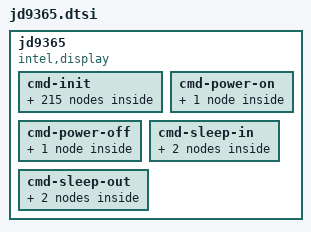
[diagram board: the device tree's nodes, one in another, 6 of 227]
	jd9365 {
		compatible = "intel,display";
		intel,display-resolution= <720 1280>;
		intel,display-dpi= <210 210>;

		/* MIPI-DSI video mode settings */
		intel,display-vid-hfp-hs-bytes = <60>;
		intel,display-vid-hbp-hs-bytes = <40>;
		intel,display-vid-hsa-hs-bytes = <30>;
		intel,display-vid-vfp-lines = <18>;
		intel,display-vid-vbp-lines = <12>;
		intel,display-vid-vsa-lines = <4>;

		intel,display-vid-mode = "pulses";
		intel,display-vid-id = <0>;
		intel,display-vid-pixel = "24packed";

		intel,display-reset = <1 1 0 5 1 50>;

		cmd-init {
			page0 {
				intel,cmd-type = <0x15>;
				intel,cmd-data = <0xE0 0x00>;
				intel,cmd-lp = <1>;
			};
			password-1 {
				intel,cmd-type = <0x15>;
				intel,cmd-data = <0xE1 0x93>;
				intel,cmd-lp = <1>;
			};
			password-2 {
				intel,cmd-type = <0x15>;
				intel,cmd-data = <0xE2 0x65>;
				intel,cmd-lp = <1>;
			};
			password-3 {
				intel,cmd-type = <0x15>;
				intel,cmd-data = <0xE3 0xF8>;
				intel,cmd-lp = <1>;
			};
			sequence_ctrl_1 {
				intel,cmd-type = <0x15>;
				intel,cmd-data = <0x70 0x10>;
				intel,cmd-lp = <1>;
			};
			sequence_ctrl_2 {
				intel,cmd-type = <0x15>;
				intel,cmd-data = <0x71 0x13>;
				intel,cmd-lp = <1>;
			};
			sequence_ctrl_3 {
				intel,cmd-type = <0x15>;
				intel,cmd-data = <0x72 0x06>;
				intel,cmd-lp = <1>;
			};
			sequence_ctrl_4 {
				intel,cmd-type = <0x15>;
				intel,cmd-data = <0x80 0x03>;
				intel,cmd-lp = <1>;
			};
			page1 {
				intel,cmd-type = <0x15>;
				intel,cmd-data = <0xE0 0x01>;
				intel,cmd-lp = <1>;
			};
			vcom_1 {
				intel,cmd-type = <0x15>;
				intel,cmd-data = <0x00 0x00>;
				intel,cmd-lp = <1>;
			};
			vcom_2 {
				intel,cmd-type = <0x15>;
				intel,cmd-data = <0x01 0xF4>;
				intel,cmd-lp = <1>;
			};
			vcom_3 {
				intel,cmd-type = <0x15>;
				intel,cmd-data = <0x03 0x00>;
				intel,cmd-lp = <1>;
			};
			vcom_4 {
				intel,cmd-type = <0x15>;
				intel,cmd-data = <0x04 0xFF>;
				intel,cmd-lp = <1>;
			};
			gamma_power_1 {
				intel,cmd-type = <0x15>;
				intel,cmd-data = <0x17 0x10>;
				intel,cmd-lp = <1>;
			};
			gamma_power_2 {
				intel,cmd-type = <0x15>;
				intel,cmd-data = <0x18 0x01>;
				intel,cmd-lp = <1>;
			};
			gamma_power_3 {
				intel,cmd-type = <0x15>;
				intel,cmd-data = <0x19 0x0E>;
				intel,cmd-lp = <1>;
			};
			gamma_power_4 {
				intel,cmd-type = <0x15>;
				intel,cmd-data = <0x1A 0x10>;
				intel,cmd-lp = <1>;
			};
			gamma_power_5 {
				intel,cmd-type = <0x15>;
				intel,cmd-data = <0x1B 0x01>;
				intel,cmd-lp = <1>;
			};
			gamma_power_6 {
				intel,cmd-type = <0x15>;
				intel,cmd-data = <0x1C 0x0E>;
				intel,cmd-lp = <1>;
			};
			gamma_power_7 {
				intel,cmd-type = <0x15>;
				intel,cmd-data = <0x1F 0x7E>;
				intel,cmd-lp = <1>;
			};
			gamma_power_8 {
				intel,cmd-type = <0x15>;
				intel,cmd-data = <0x20 0x24>;
				intel,cmd-lp = <1>;
			};
			gamma_power_9 {
				intel,cmd-type = <0x15>;
				intel,cmd-data = <0x21 0x24>;
				intel,cmd-lp = <1>;
			};
			gamma_power_10 {
				intel,cmd-type = <0x15>;
				intel,cmd-data = <0x12 0x4E>;
				intel,cmd-lp = <1>;
			};
			rgb_cyc_1 {
				intel,cmd-type = <0x15>;
				intel,cmd-data = <0x37 0x09>;
				intel,cmd-lp = <1>;
			};
			rgb_cyc_2 {
				intel,cmd-type = <0x15>;
				intel,cmd-data = <0x38 0x04>;
				intel,cmd-lp = <1>;
			};
			rgb_cyc_3 {
				intel,cmd-type = <0x15>;
				intel,cmd-data = <0x39 0x08>;
				intel,cmd-lp = <1>;
			};
			rgb_cyc_4 {
				intel,cmd-type = <0x15>;
				intel,cmd-data = <0x3A 0x12>;
				intel,cmd-lp = <1>;
			};
			rgb_cyc_5 {
				intel,cmd-type = <0x15>;
				intel,cmd-data = <0x3C 0x78>;
				intel,cmd-lp = <1>;
			};
			rgb_cyc_6 {
				intel,cmd-type = <0x15>;
				intel,cmd-data = <0x3D 0xFF>;
				intel,cmd-lp = <1>;
			};
			rgb_cyc_7 {
				intel,cmd-type = <0x15>;
				intel,cmd-data = <0x3E 0xFF>;
				intel,cmd-lp = <1>;
			};
			rgb_cyc_8 {
				intel,cmd-type = <0x15>;
				intel,cmd-data = <0x3F 0x7F>;
				intel,cmd-lp = <1>;
			};
			tcon_set_1 {
				intel,cmd-type = <0x15>;
				intel,cmd-data = <0x40 0x04>;
				intel,cmd-lp = <1>;
			};
			tcon_set_2 {
				intel,cmd-type = <0x15>;
				intel,cmd-data = <0x41 0xA0>;
				intel,cmd-lp = <1>;
			};
			power_voltage_1 {
				intel,cmd-type = <0x15>;
				intel,cmd-data = <0x0A 0x18>;
				intel,cmd-lp = <1>;
			};
			power_voltage_2 {
				intel,cmd-type = <0x15>;
				intel,cmd-data = <0x55 0x02>;
				intel,cmd-lp = <1>;
			};
			power_voltage_3 {
				intel,cmd-type = <0x15>;
				intel,cmd-data = <0x56 0x01>;
				intel,cmd-lp = <1>;
			};
			power_voltage_4 {
				intel,cmd-type = <0x15>;
				intel,cmd-data = <0x57 0x69>;
				intel,cmd-lp = <1>;
			};
			power_voltage_5 {
				intel,cmd-type = <0x15>;
				intel,cmd-data = <0x58 0x0A>;
				intel,cmd-lp = <1>;
			};
			power_voltage_6 {
				intel,cmd-type = <0x15>;
				intel,cmd-data = <0x59 0x2A>;
				intel,cmd-lp = <1>;
			};
			power_voltage_7 {
				intel,cmd-type = <0x15>;
				intel,cmd-data = <0x5A 0x2B>;
				intel,cmd-lp = <1>;
			};
			power_voltage_8 {
				intel,cmd-type = <0x15>;
				intel,cmd-data = <0x5B 0x13>;
				intel,cmd-lp = <1>;
			};
			gamma_1 {
				intel,cmd-type = <0x15>;
				intel,cmd-data = <0x5D 0x7C>;
				intel,cmd-lp = <1>;
			};
			gamma_2 {
				intel,cmd-type = <0x15>;
				intel,cmd-data = <0x5E 0x56>;
				intel,cmd-lp = <1>;
			};
			gamma_3 {
				intel,cmd-type = <0x15>;
				intel,cmd-data = <0x5F 0x44>;
				intel,cmd-lp = <1>;
			};
			gamma_4 {
				intel,cmd-type = <0x15>;
				intel,cmd-data = <0x60 0x36>;
				intel,cmd-lp = <1>;
			};
			gamma_5 {
				intel,cmd-type = <0x15>;
				intel,cmd-data = <0x61 0x32>;
				intel,cmd-lp = <1>;
			};
			gamma_6 {
				intel,cmd-type = <0x15>;
				intel,cmd-data = <0x62 0x23>;
				intel,cmd-lp = <1>;
			};
			gamma_7 {
				intel,cmd-type = <0x15>;
				intel,cmd-data = <0x63 0x28>;
				intel,cmd-lp = <1>;
			};
			gamma_8 {
				intel,cmd-type = <0x15>;
				intel,cmd-data = <0x64 0x12>;
				intel,cmd-lp = <1>;
			};
			gamma_9 {
				intel,cmd-type = <0x15>;
				intel,cmd-data = <0x65 0x2B>;
				intel,cmd-lp = <1>;
			};
			gamma_10 {
				intel,cmd-type = <0x15>;
				intel,cmd-data = <0x66 0x29>;
				intel,cmd-lp = <1>;
			};
			gamma_11 {
				intel,cmd-type = <0x15>;
				intel,cmd-data = <0x67 0x29>;
				intel,cmd-lp = <1>;
			};
			gamma_12 {
				intel,cmd-type = <0x15>;
				intel,cmd-data = <0x68 0x47>;
				intel,cmd-lp = <1>;
			};
			gamma_13 {
				intel,cmd-type = <0x15>;
				intel,cmd-data = <0x69 0x36>;
				intel,cmd-lp = <1>;
			};
			gamma_14 {
				intel,cmd-type = <0x15>;
				intel,cmd-data = <0x6A 0x3E>;
				intel,cmd-lp = <1>;
			};
			gamma_15 {
				intel,cmd-type = <0x15>;
				intel,cmd-data = <0x6B 0x32>;
				intel,cmd-lp = <1>;
			};
			gamma_16 {
				intel,cmd-type = <0x15>;
				intel,cmd-data = <0x6C 0x31>;
				intel,cmd-lp = <1>;
			};
			gamma_17 {
				intel,cmd-type = <0x15>;
				intel,cmd-data = <0x6D 0x26>;
				intel,cmd-lp = <1>;
			};
			gamma_18 {
				intel,cmd-type = <0x15>;
				intel,cmd-data = <0x6E 0x1A>;
				intel,cmd-lp = <1>;
			};
			gamma_19 {
				intel,cmd-type = <0x15>;
				intel,cmd-data = <0x6F 0x01>;
				intel,cmd-lp = <1>;
			};
			gamma_20 {
				intel,cmd-type = <0x15>;
				intel,cmd-data = <0x70 0x7C>;
				intel,cmd-lp = <1>;
			};
			gamma_21 {
				intel,cmd-type = <0x15>;
				intel,cmd-data = <0x71 0x56>;
				intel,cmd-lp = <1>;
			};
			gamma_22 {
				intel,cmd-type = <0x15>;
				intel,cmd-data = <0x72 0x44>;
				intel,cmd-lp = <1>;
			};
			gamma_23 {
				intel,cmd-type = <0x15>;
				intel,cmd-data = <0x73 0x36>;
				intel,cmd-lp = <1>;
			};
			gamma_24 {
				intel,cmd-type = <0x15>;
				intel,cmd-data = <0x74 0x32>;
				intel,cmd-lp = <1>;
			};
			gamma_25 {
				intel,cmd-type = <0x15>;
				intel,cmd-data = <0x75 0x23>;
				intel,cmd-lp = <1>;
			};
			gamma_26 {
				intel,cmd-type = <0x15>;
				intel,cmd-data = <0x76 0x28>;
				intel,cmd-lp = <1>;
			};
			gamma_27 {
				intel,cmd-type = <0x15>;
				intel,cmd-data = <0x77 0x12>;
				intel,cmd-lp = <1>;
			};
			gamma_28 {
				intel,cmd-type = <0x15>;
				intel,cmd-data = <0x78 0x2B>;
				intel,cmd-lp = <1>;
			};
			gamma_29 {
				intel,cmd-type = <0x15>;
				intel,cmd-data = <0x79 0x29>;
				intel,cmd-lp = <1>;
			};
			gamma_30 {
				intel,cmd-type = <0x15>;
				intel,cmd-data = <0x7A 0x29>;
				intel,cmd-lp = <1>;
			};
			gamma_31 {
				intel,cmd-type = <0x15>;
				intel,cmd-data = <0x7B 0x47>;
				intel,cmd-lp = <1>;
			};
			gamma_32 {
				intel,cmd-type = <0x15>;
				intel,cmd-data = <0x7C 0x36>;
				intel,cmd-lp = <1>;
			};
			gamma_33 {
				intel,cmd-type = <0x15>;
				intel,cmd-data = <0x7D 0x3E>;
				intel,cmd-lp = <1>;
			};
			gamma_34 {
				intel,cmd-type = <0x15>;
				intel,cmd-data = <0x7E 0x32>;
				intel,cmd-lp = <1>;
			};
			gamma_35 {
				intel,cmd-type = <0x15>;
				intel,cmd-data = <0x7F 0x31>;
				intel,cmd-lp = <1>;
			};
			gamma_36 {
				intel,cmd-type = <0x15>;
				intel,cmd-data = <0x80 0x26>;
				intel,cmd-lp = <1>;
			};
			gamma_37 {
				intel,cmd-type = <0x15>;
				intel,cmd-data = <0x81 0x1A>;
				intel,cmd-lp = <1>;
			};
			gamma_38 {
				intel,cmd-type = <0x15>;
				intel,cmd-data = <0x82 0x01>;
				intel,cmd-lp = <1>;
			};
			page2 {
				intel,cmd-type = <0x15>;
				intel,cmd-data = <0xE0 0x02>;
				intel,cmd-lp = <1>;
			};
			gip_l_1 {
				intel,cmd-type = <0x15>;
				intel,cmd-data = <0x00 0x08>;
				intel,cmd-lp = <1>;
			};
			gip_l_2 {
				intel,cmd-type = <0x15>;
				intel,cmd-data = <0x01 0x0A>;
				intel,cmd-lp = <1>;
			};
			gip_l_3 {
				intel,cmd-type = <0x15>;
				intel,cmd-data = <0x02 0x04>;
				intel,cmd-lp = <1>;
			};
			gip_l_4 {
				intel,cmd-type = <0x15>;
				intel,cmd-data = <0x03 0x06>;
				intel,cmd-lp = <1>;
			};
			gip_l_5 {
				intel,cmd-type = <0x15>;
				intel,cmd-data = <0x04 0x00>;
				intel,cmd-lp = <1>;
			};
			gip_l_6 {
				intel,cmd-type = <0x15>;
				intel,cmd-data = <0x05 0x02>;
				intel,cmd-lp = <1>;
			};
			gip_l_7 {
				intel,cmd-type = <0x15>;
				intel,cmd-data = <0x06 0x1F>;
				intel,cmd-lp = <1>;
			};
			gip_l_8 {
				intel,cmd-type = <0x15>;
				intel,cmd-data = <0x07 0x1F>;
				intel,cmd-lp = <1>;
			};
			gip_l_9 {
				intel,cmd-type = <0x15>;
				intel,cmd-data = <0x08 0x1F>;
				intel,cmd-lp = <1>;
			};
			gip_l_10 {
				intel,cmd-type = <0x15>;
				intel,cmd-data = <0x09 0x1F>;
				intel,cmd-lp = <1>;
			};
			gip_l_11 {
				intel,cmd-type = <0x15>;
				intel,cmd-data = <0x0A 0x1E>;
				intel,cmd-lp = <1>;
			};
			gip_l_12 {
				intel,cmd-type = <0x15>;
				intel,cmd-data = <0x0B 0x1F>;
				intel,cmd-lp = <1>;
			};
			gip_l_13 {
				intel,cmd-type = <0x15>;
				intel,cmd-data = <0x0C 0x1F>;
				intel,cmd-lp = <1>;
			};
			gip_l_14 {
				intel,cmd-type = <0x15>;
				intel,cmd-data = <0x0D 0x17>;
				intel,cmd-lp = <1>;
			};
			gip_l_15 {
				intel,cmd-type = <0x15>;
				intel,cmd-data = <0x0E 0x37>;
				intel,cmd-lp = <1>;
			};
			gip_l_16 {
				intel,cmd-type = <0x15>;
				intel,cmd-data = <0x0F 0x1F>;
				intel,cmd-lp = <1>;
			};
			gip_l_17 {
				intel,cmd-type = <0x15>;
				intel,cmd-data = <0x10 0x1F>;
				intel,cmd-lp = <1>;
			};
			gip_l_18 {
				intel,cmd-type = <0x15>;
				intel,cmd-data = <0x11 0x1F>;
				intel,cmd-lp = <1>;
			};
			gip_l_19 {
				intel,cmd-type = <0x15>;
				intel,cmd-data = <0x12 0x1F>;
				intel,cmd-lp = <1>;
			};
			gip_l_20 {
				intel,cmd-type = <0x15>;
				intel,cmd-data = <0x13 0x1F>;
				intel,cmd-lp = <1>;
			};
			gip_l_21 {
				intel,cmd-type = <0x15>;
				intel,cmd-data = <0x14 0x1F>;
				intel,cmd-lp = <1>;
			};
			gip_l_22 {
				intel,cmd-type = <0x15>;
				intel,cmd-data = <0x15 0x1F>;
				intel,cmd-lp = <1>;
			};
			gip_r_1 {
				intel,cmd-type = <0x15>;
				intel,cmd-data = <0x16 0x09>;
				intel,cmd-lp = <1>;
			};
			gip_r_2 {
				intel,cmd-type = <0x15>;
				intel,cmd-data = <0x17 0x0B>;
				intel,cmd-lp = <1>;
			};
			gip_r_3 {
				intel,cmd-type = <0x15>;
				intel,cmd-data = <0x18 0x05>;
				intel,cmd-lp = <1>;
			};
			gip_r_4 {
				intel,cmd-type = <0x15>;
				intel,cmd-data = <0x19 0x07>;
				intel,cmd-lp = <1>;
			};
			gip_r_5 {
				intel,cmd-type = <0x15>;
				intel,cmd-data = <0x1A 0x01>;
				intel,cmd-lp = <1>;
			};
			gip_r_6 {
				intel,cmd-type = <0x15>;
				intel,cmd-data = <0x1B 0x03>;
				intel,cmd-lp = <1>;
			};
			gip_r_7 {
				intel,cmd-type = <0x15>;
				intel,cmd-data = <0x1C 0x1F>;
				intel,cmd-lp = <1>;
			};
			gip_r_8 {
				intel,cmd-type = <0x15>;
				intel,cmd-data = <0x1D 0x1F>;
				intel,cmd-lp = <1>;
			};
			gip_r_9 {
				intel,cmd-type = <0x15>;
				intel,cmd-data = <0x1E 0x1F>;
				intel,cmd-lp = <1>;
			};
			gip_r_10 {
				intel,cmd-type = <0x15>;
				intel,cmd-data = <0x1F 0x1F>;
				intel,cmd-lp = <1>;
			};
			gip_r_11 {
				intel,cmd-type = <0x15>;
				intel,cmd-data = <0x20 0x1E>;
				intel,cmd-lp = <1>;
			};
			gip_r_12 {
				intel,cmd-type = <0x15>;
				intel,cmd-data = <0x21 0x1F>;
				intel,cmd-lp = <1>;
			};
			gip_r_13 {
				intel,cmd-type = <0x15>;
				intel,cmd-data = <0x22 0x1F>;
				intel,cmd-lp = <1>;
			};
			gip_r_14 {
				intel,cmd-type = <0x15>;
				intel,cmd-data = <0x23 0x17>;
				intel,cmd-lp = <1>;
			};
			gip_r_15 {
				intel,cmd-type = <0x15>;
				intel,cmd-data = <0x24 0x37>;
				intel,cmd-lp = <1>;
			};
			gip_r_16 {
				intel,cmd-type = <0x15>;
				intel,cmd-data = <0x25 0x1F>;
				intel,cmd-lp = <1>;
			};
			gip_r_17 {
				intel,cmd-type = <0x15>;
				intel,cmd-data = <0x26 0x1F>;
				intel,cmd-lp = <1>;
			};
			gip_r_18 {
				intel,cmd-type = <0x15>;
				intel,cmd-data = <0x27 0x1F>;
				intel,cmd-lp = <1>;
			};
			gip_r_19 {
				intel,cmd-type = <0x15>;
				intel,cmd-data = <0x28 0x1F>;
				intel,cmd-lp = <1>;
			};
			gip_r_20 {
				intel,cmd-type = <0x15>;
				intel,cmd-data = <0x29 0x1F>;
				intel,cmd-lp = <1>;
			};
			gip_r_21 {
				intel,cmd-type = <0x15>;
				intel,cmd-data = <0x2A 0x1F>;
				intel,cmd-lp = <1>;
			};
			gip_r_22 {
				intel,cmd-type = <0x15>;
				intel,cmd-data = <0x2B 0x1F>;
				intel,cmd-lp = <1>;
			};
			gip_l_gs_1 {
				intel,cmd-type = <0x15>;
				intel,cmd-data = <0x2C 0x07>;
				intel,cmd-lp = <1>;
			};
			gip_l_gs_2 {
				intel,cmd-type = <0x15>;
				intel,cmd-data = <0x2D 0x05>;
				intel,cmd-lp = <1>;
			};
			gip_l__gs_3 {
				intel,cmd-type = <0x15>;
				intel,cmd-data = <0x2E 0x0B>;
				intel,cmd-lp = <1>;
			};
			gip_l_gs_4 {
				intel,cmd-type = <0x15>;
				intel,cmd-data = <0x2F 0x09>;
				intel,cmd-lp = <1>;
			};
			gip_l_gs_5 {
				intel,cmd-type = <0x15>;
				intel,cmd-data = <0x30 0x03>;
				intel,cmd-lp = <1>;
			};
			gip_l_gs_6 {
				intel,cmd-type = <0x15>;
				intel,cmd-data = <0x31 0x01>;
				intel,cmd-lp = <1>;
			};
			gip_l_gs_7 {
				intel,cmd-type = <0x15>;
				intel,cmd-data = <0x32 0x1F>;
				intel,cmd-lp = <1>;
			};
			gip_l_gs_8 {
				intel,cmd-type = <0x15>;
				intel,cmd-data = <0x33 0x1F>;
				intel,cmd-lp = <1>;
			};
			gip_l_gs_9 {
				intel,cmd-type = <0x15>;
				intel,cmd-data = <0x34 0x1F>;
				intel,cmd-lp = <1>;
			};
			gip_l_gs_10 {
				intel,cmd-type = <0x15>;
				intel,cmd-data = <0x35 0x1F>;
				intel,cmd-lp = <1>;
			};
			gip_l_gs_11 {
				intel,cmd-type = <0x15>;
				intel,cmd-data = <0x36 0x1F>;
				intel,cmd-lp = <1>;
			};
			gip_l_gs_12 {
				intel,cmd-type = <0x15>;
				intel,cmd-data = <0x37 0x1E>;
				intel,cmd-lp = <1>;
			};
			gip_l_gs_13 {
				intel,cmd-type = <0x15>;
				intel,cmd-data = <0x38 0x1F>;
				intel,cmd-lp = <1>;
			};
			gip_l_gs_14 {
				intel,cmd-type = <0x15>;
				intel,cmd-data = <0x39 0x17>;
				intel,cmd-lp = <1>;
			};
			gip_l_gs_15 {
				intel,cmd-type = <0x15>;
				intel,cmd-data = <0x3A 0x37>;
				intel,cmd-lp = <1>;
			};
			gip_l_gs_16 {
				intel,cmd-type = <0x15>;
				intel,cmd-data = <0x3B 0x1F>;
				intel,cmd-lp = <1>;
			};
			gip_l_gs_17 {
				intel,cmd-type = <0x15>;
				intel,cmd-data = <0x3C 0x1F>;
				intel,cmd-lp = <1>;
			};
			gip_l_gs_18 {
				intel,cmd-type = <0x15>;
				intel,cmd-data = <0x3D 0x1F>;
				intel,cmd-lp = <1>;
			};
			gip_l_gs_19 {
				intel,cmd-type = <0x15>;
				intel,cmd-data = <0x3E 0x1F>;
				intel,cmd-lp = <1>;
			};
			gip_l_gs_20 {
				intel,cmd-type = <0x15>;
				intel,cmd-data = <0x3F 0x1F>;
				intel,cmd-lp = <1>;
			};
			gip_l_gs_21 {
				intel,cmd-type = <0x15>;
				intel,cmd-data = <0x40 0x1F>;
				intel,cmd-lp = <1>;
			};
			gip_l_gs_22 {
				intel,cmd-type = <0x15>;
				intel,cmd-data = <0x41 0x1F>;
				intel,cmd-lp = <1>;
			};
			gip_r_gs_1 {
				intel,cmd-type = <0x15>;
				intel,cmd-data = <0x42 0x06>;
				intel,cmd-lp = <1>;
			};
			gip_r_gs_2 {
				intel,cmd-type = <0x15>;
				intel,cmd-data = <0x43 0x04>;
				intel,cmd-lp = <1>;
			};
			gip_r_gs_3 {
				intel,cmd-type = <0x15>;
				intel,cmd-data = <0x44 0x0A>;
				intel,cmd-lp = <1>;
			};
			gip_r_gs_4 {
				intel,cmd-type = <0x15>;
				intel,cmd-data = <0x45 0x08>;
				intel,cmd-lp = <1>;
			};
			gip_r_gs_5 {
				intel,cmd-type = <0x15>;
				intel,cmd-data = <0x46 0x02>;
				intel,cmd-lp = <1>;
			};
			gip_r_gs_6 {
				intel,cmd-type = <0x15>;
				intel,cmd-data = <0x47 0x00>;
				intel,cmd-lp = <1>;
			};
			gip_r_gs_7 {
				intel,cmd-type = <0x15>;
				intel,cmd-data = <0x48 0x1F>;
				intel,cmd-lp = <1>;
			};
			gip_r_gs_8 {
				intel,cmd-type = <0x15>;
				intel,cmd-data = <0x49 0x1F>;
				intel,cmd-lp = <1>;
			};
			gip_r_gs_9 {
				intel,cmd-type = <0x15>;
				intel,cmd-data = <0x4A 0x1F>;
				intel,cmd-lp = <1>;
			};
			gip_r_gs_10 {
				intel,cmd-type = <0x15>;
				intel,cmd-data = <0x4B 0x1F>;
				intel,cmd-lp = <1>;
			};
			gip_r_gs_11 {
				intel,cmd-type = <0x15>;
				intel,cmd-data = <0x4C 0x1F>;
				intel,cmd-lp = <1>;
			};
			gip_r_gs_12 {
				intel,cmd-type = <0x15>;
				intel,cmd-data = <0x4D 0x1E>;
				intel,cmd-lp = <1>;
			};
			gip_r_gs_13 {
				intel,cmd-type = <0x15>;
				intel,cmd-data = <0x4E 0x1F>;
				intel,cmd-lp = <1>;
			};
			gip_r_gs_14 {
				intel,cmd-type = <0x15>;
				intel,cmd-data = <0x4F 0x17>;
				intel,cmd-lp = <1>;
			};
			gip_r_gs_15 {
				intel,cmd-type = <0x15>;
				intel,cmd-data = <0x50 0x37>;
				intel,cmd-lp = <1>;
			};
			gip_r_gs_16 {
				intel,cmd-type = <0x15>;
				intel,cmd-data = <0x51 0x1F>;
				intel,cmd-lp = <1>;
			};
			gip_r_gs_17 {
				intel,cmd-type = <0x15>;
				intel,cmd-data = <0x52 0x1F>;
				intel,cmd-lp = <1>;
			};
			gip_r_gs_18 {
				intel,cmd-type = <0x15>;
				intel,cmd-data = <0x53 0x1F>;
				intel,cmd-lp = <1>;
			};
			gip_r_gs_19 {
				intel,cmd-type = <0x15>;
				intel,cmd-data = <0x54 0x1F>;
				intel,cmd-lp = <1>;
			};
			gip_r_gs_20 {
				intel,cmd-type = <0x15>;
				intel,cmd-data = <0x55 0x1F>;
				intel,cmd-lp = <1>;
			};
			gip_r_gs_21 {
				intel,cmd-type = <0x15>;
				intel,cmd-data = <0x56 0x1F>;
				intel,cmd-lp = <1>;
			};
			gip_r_gs_22 {
				intel,cmd-type = <0x15>;
				intel,cmd-data = <0x57 0x1F>;
				intel,cmd-lp = <1>;
			};
			gip_1 {
				intel,cmd-type = <0x15>;
				intel,cmd-data = <0x58 0x10>;
				intel,cmd-lp = <1>;
			};
			gip_2 {
				intel,cmd-type = <0x15>;
				intel,cmd-data = <0x59 0x00>;
				intel,cmd-lp = <1>;
			};
			gip_3 {
				intel,cmd-type = <0x15>;
				intel,cmd-data = <0x5A 0x00>;
				intel,cmd-lp = <1>;
			};
			gip_4 {
				intel,cmd-type = <0x15>;
				intel,cmd-data = <0x5B 0x30>;
				intel,cmd-lp = <1>;
			};
			gip_5 {
				intel,cmd-type = <0x15>;
				intel,cmd-data = <0x5C 0x05>;
				intel,cmd-lp = <1>;
			};
			gip_6 {
				intel,cmd-type = <0x15>;
				intel,cmd-data = <0x5D 0x30>;
				intel,cmd-lp = <1>;
			};
			gip_7 {
				intel,cmd-type = <0x15>;
				intel,cmd-data = <0x5E 0x01>;
				intel,cmd-lp = <1>;
			};
			gip_8 {
				intel,cmd-type = <0x15>;
				intel,cmd-data = <0x5F 0x02>;
				intel,cmd-lp = <1>;
			};
			gip_9 {
				intel,cmd-type = <0x15>;
				intel,cmd-data = <0x60 0x00>;
				intel,cmd-lp = <1>;
			};
			gip_10 {
				intel,cmd-type = <0x15>;
				intel,cmd-data = <0x61 0x00>;
				intel,cmd-lp = <1>;
			};
			gip_11 {
				intel,cmd-type = <0x15>;
				intel,cmd-data = <0x62 0x00>;
				intel,cmd-lp = <1>;
			};
			gip_12 {
				intel,cmd-type = <0x15>;
				intel,cmd-data = <0x63 0x03>;
				intel,cmd-lp = <1>;
			};
			gip_13 {
				intel,cmd-type = <0x15>;
				intel,cmd-data = <0x64 0x6A>;
				intel,cmd-lp = <1>;
			};
			gip_14 {
				intel,cmd-type = <0x15>;
				intel,cmd-data = <0x65 0x00>;
				intel,cmd-lp = <1>;
			};
			gip_15 {
				intel,cmd-type = <0x15>;
				intel,cmd-data = <0x66 0x00>;
				intel,cmd-lp = <1>;
			};
			gip_16 {
				intel,cmd-type = <0x15>;
				intel,cmd-data = <0x67 0x73>;
				intel,cmd-lp = <1>;
			};
			gip_17 {
				intel,cmd-type = <0x15>;
				intel,cmd-data = <0x68 0x09>;
				intel,cmd-lp = <1>;
			};
			gip_18 {
				intel,cmd-type = <0x15>;
				intel,cmd-data = <0x69 0x06>;
				intel,cmd-lp = <1>;
			};
			gip_19 {
				intel,cmd-type = <0x15>;
				intel,cmd-data = <0x6A 0x6A>;
				intel,cmd-lp = <1>;
			};
			gip_20 {
				intel,cmd-type = <0x15>;
				intel,cmd-data = <0x6B 0x08>;
				intel,cmd-lp = <1>;
			};
			gip_21 {
				intel,cmd-type = <0x15>;
				intel,cmd-data = <0x6C 0x00>;
				intel,cmd-lp = <1>;
			};
			gip_22 {
				intel,cmd-type = <0x15>;
				intel,cmd-data = <0x6D 0x04>;
				intel,cmd-lp = <1>;
			};
			gip_23 {
				intel,cmd-type = <0x15>;
				intel,cmd-data = <0x6E 0x04>;
				intel,cmd-lp = <1>;
			};
			gip_24 {
				intel,cmd-type = <0x15>;
				intel,cmd-data = <0x6F 0x88>;
				intel,cmd-lp = <1>;
			};
			gip_25 {
				intel,cmd-type = <0x15>;
				intel,cmd-data = <0x70 0x00>;
				intel,cmd-lp = <1>;
			};
			gip_26 {
				intel,cmd-type = <0x15>;
				intel,cmd-data = <0x71 0x00>;
				intel,cmd-lp = <1>;
			};
			gip_27 {
				intel,cmd-type = <0x15>;
				intel,cmd-data = <0x72 0x06>;
				intel,cmd-lp = <1>;
			};
			gip_28 {
				intel,cmd-type = <0x15>;
				intel,cmd-data = <0x73 0x7B>;
				intel,cmd-lp = <1>;
			};
			gip_29 {
				intel,cmd-type = <0x15>;
				intel,cmd-data = <0x74 0x00>;
				intel,cmd-lp = <1>;
			};
			gip_30 {
				intel,cmd-type = <0x15>;
				intel,cmd-data = <0x75 0x80>;
				intel,cmd-lp = <1>;
			};
			gip_31 {
				intel,cmd-type = <0x15>;
				intel,cmd-data = <0x76 0x00>;
				intel,cmd-lp = <1>;
			};
			gip_32 {
				intel,cmd-type = <0x15>;
				intel,cmd-data = <0x77 0x5D>;
				intel,cmd-lp = <1>;
			};
			gip_33 {
				intel,cmd-type = <0x15>;
				intel,cmd-data = <0x78 0x23>;
				intel,cmd-lp = <1>;
			};
			gip_34 {
				intel,cmd-type = <0x15>;
				intel,cmd-data = <0x79 0x1F>;
				intel,cmd-lp = <1>;
			};
			gip_35 {
				intel,cmd-type = <0x15>;
				intel,cmd-data = <0x7A 0x00>;
				intel,cmd-lp = <1>;
			};
			gip_36 {
				intel,cmd-type = <0x15>;
				intel,cmd-data = <0x7B 0x00>;
				intel,cmd-lp = <1>;
			};
			gip_37 {
				intel,cmd-type = <0x15>;
				intel,cmd-data = <0x7C 0x00>;
				intel,cmd-lp = <1>;
			};
			gip_38 {
				intel,cmd-type = <0x15>;
				intel,cmd-data = <0x7D 0x03>;
				intel,cmd-lp = <1>;
			};
			gip_39 {
				intel,cmd-type = <0x15>;
				intel,cmd-data = <0x7E 0x7B>;
				intel,cmd-lp = <1>;
			};
			page0_end {
				intel,cmd-type = <0x15>;
				intel,cmd-data = <0xE0 0x00>;
				intel,cmd-lp = <1>;
			};
			set-cabc-1 {
				intel,cmd-type = <0x15>;
				intel,cmd-data = <0x51 0xFF>;
				intel,cmd-lp = <1>;
			};
			set-cabc-2 {
				intel,cmd-type = <0x15>;
				intel,cmd-data = <0x53 0x24>;
				intel,cmd-lp = <1>;
			};
			set-cabc-3 {
				intel,cmd-type = <0x15>;
				intel,cmd-data = <0x55 0x01>;
				intel,cmd-lp = <1>;
				intel,cmd-delay = <5>;
			};
			set-ctl {
				intel,cmd-type = <0x15>;
				intel,cmd-data = <0x36 0x08>;
				intel,cmd-lp = <1>;
			};
			sleep-out {
				intel,cmd-type = <0x05>;
				intel,cmd-data = <0x11>;
				intel,cmd-lp = <1>;
				intel,cmd-delay = <120>;
			};
			display-on{
				intel,cmd-type = <0x05>;
				intel,cmd-data = <0x29>;
				intel,cmd-lp = <1>;
				intel,cmd-delay = <5>;
			};
			te_set {
				intel,cmd-type = <0x15>;
				intel,cmd-data = <0x35 0x00>;
				intel,cmd-lp = <1>;
			};
		};

		cmd-power-on {
			display-on{
				intel,cmd-type = <0x05>;
				intel,cmd-data = <0x29>;
				intel,cmd-lp = <1>;
				intel,cmd-delay = <5>;
			};
		};

		cmd-power-off {
			display-off{
				intel,cmd-type = <0x05>;
				intel,cmd-data = <0x28>;
				intel,cmd-lp = <1>;
				intel,cmd-delay = <50>;
			};
		};

		cmd-sleep-in {
			display-off{
				intel,cmd-type = <0x05>;
				intel,cmd-data = <0x28>;
				intel,cmd-lp = <1>;
				intel,cmd-delay = <100>;
			};
			sleep-in{
				intel,cmd-type = <0x05>;
				intel,cmd-data = <0x10>;
				intel,cmd-lp = <1>;
			};
		};

		cmd-sleep-out {
			sleep-out{
				intel,cmd-type = <0x05>;
				intel,cmd-data = <0x11>;
				intel,cmd-lp = <1>;
				intel,cmd-delay = <120>;
			};
			display-on{
				intel,cmd-type = <0x05>;
				intel,cmd-data = <0x29>;
				intel,cmd-lp = <1>;
				intel,cmd-delay = <5>;
			};
		};
	};
